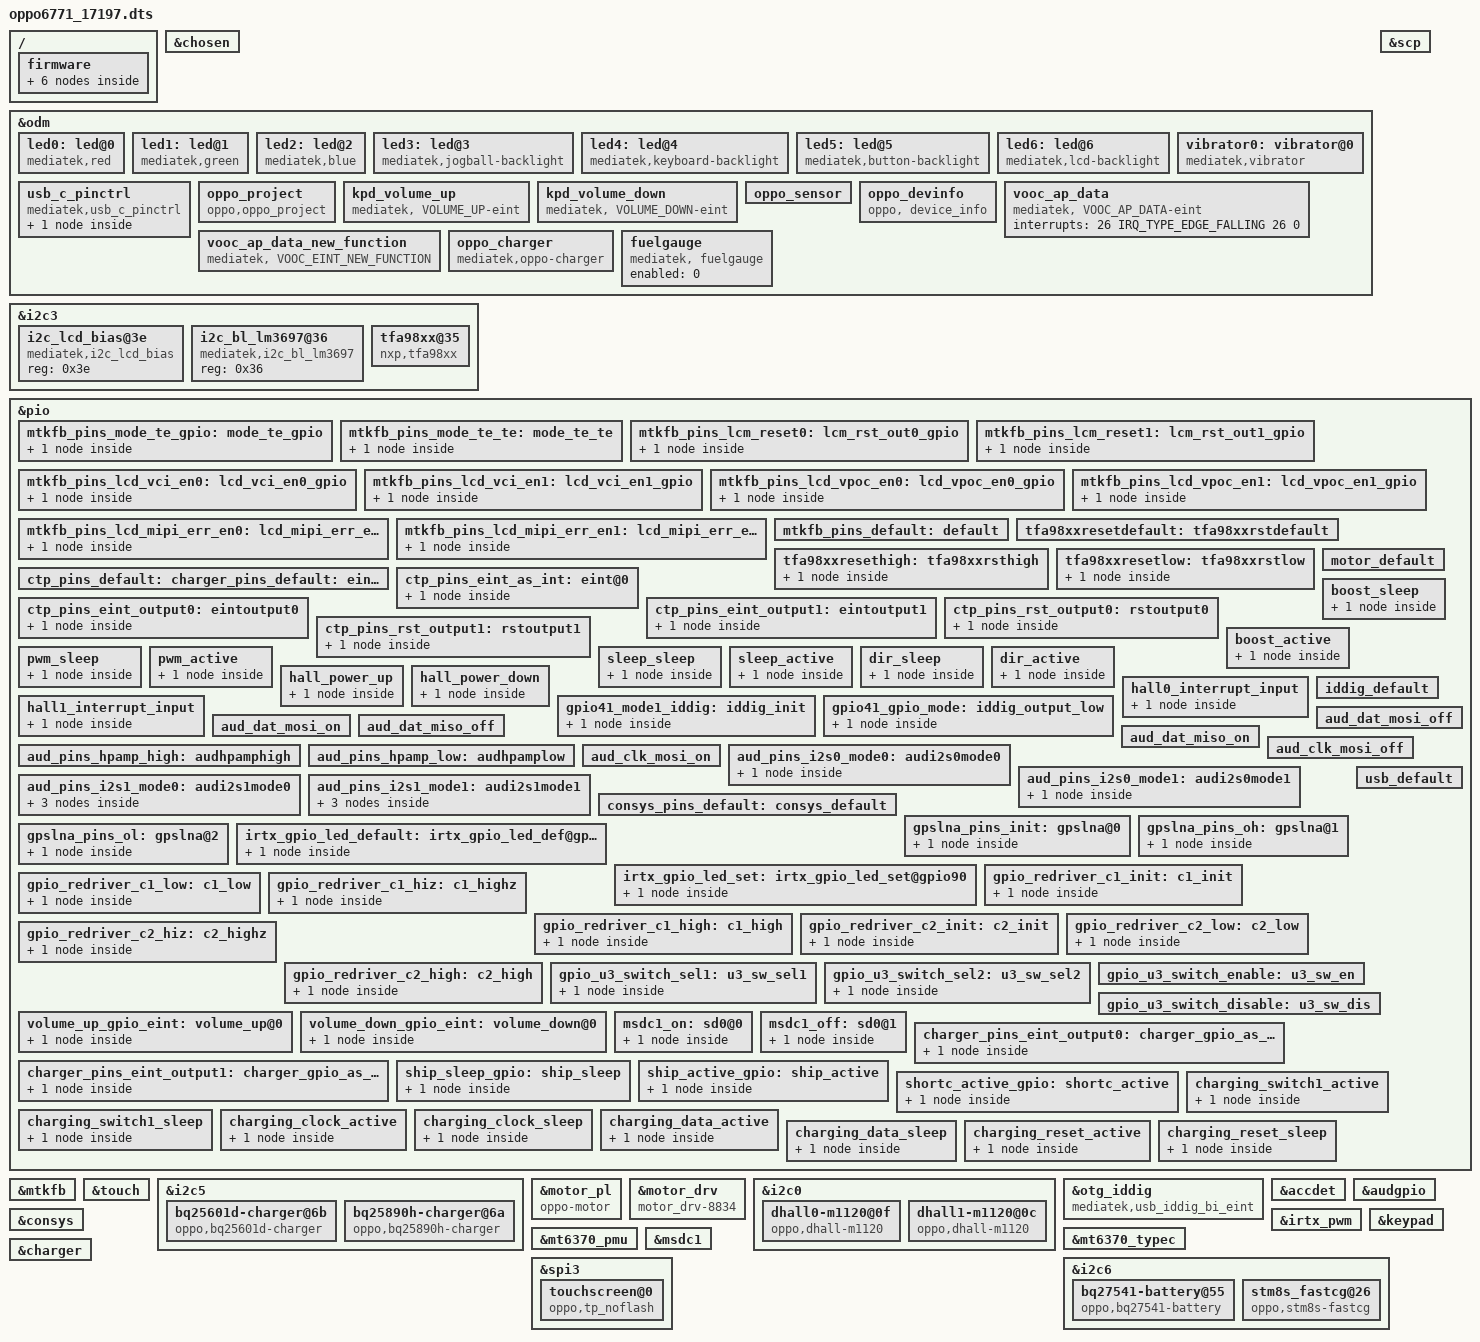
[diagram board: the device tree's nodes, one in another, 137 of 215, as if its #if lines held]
/*
 * Mediatek's mt6771 SoC device tree source
 *
 * Copyright (C) 2016 MediaTek Inc.
 *
 * This program is free software; you can redistribute it and/or modify
 * it under the terms of the GNU General Public License version 2 as
 * published by the Free Software Foundation.
 *
 * This program is distributed in the hope that it will be useful,
 * but WITHOUT ANY WARRANTY; without even the implied warranty of
 * MERCHANTABILITY or FITNESS FOR A PARTICULAR PURPOSE.
 * See http://www.gnu.org/licenses/gpl-2.0.html for more details.
 */
/dts-v1/;
/plugin/;
#include <dt-bindings/interrupt-controller/irq.h>
#include <dt-bindings/interrupt-controller/arm-gic.h>
#include <dt-bindings/pinctrl/mt6771-pinfunc.h>

/* chosen */
&chosen {
	/* fpga may has no lk, we need to specify display info here */
	/* fb buffer is reserved using this dts by memory node above */

	atag,videolfb-fb_base_l = <0x5e605000>;
	atag,videolfb-fb_base_h = <0x0>;
	atag,videolfb-islcmfound = <1>;
	atag,videolfb-islcm_inited = <0>;
	atag,videolfb-fps= <6000>;
	atag,videolfb-vramSize= <0x017bb000>;
	atag,videolfb-lcmname= "nt35595_fhd_dsi_cmd_truly_nt50358_drv";
};

/ {
	firmware {
		android {
			compatible = "android,firmware";
#ifndef CONFIG_MTK_LDVT
#ifdef CONFIG_MTK_AVB20_SUPPORT
			vbmeta {
				compatible = "android,vbmeta";
#ifndef CONFIG_MTK_AB_OTA_UPDATER
				parts = "vbmeta,boot,system,vendor,recovery";
#else
				parts = "vbmeta,boot,system,vendor";
#endif
			};
#endif
			fstab {
				compatible = "android,fstab";
#if !defined(CONFIG_SYSTEM_AS_ROOT) && !defined(CONFIG_MTK_AB_OTA_UPDATER)
				system {
					compatible = "android,system";
					dev = "/dev/block/platform/bootdevice/by-name/system";
					type = "ext4";
					mnt_flags = "ro";
#ifndef CONFIG_MTK_DM_VERITY_OFF
#ifdef CONFIG_MTK_AVB20_SUPPORT
					fsmgr_flags = "wait,avb";
#else
					fsmgr_flags = "wait,verify";
#endif
#else
					fsmgr_flags = "wait";
#endif
				};
#endif
#ifndef CONFIG_MTK_LATE_MOUNT
				vendor {
					compatible = "android,vendor";
					dev = "/dev/block/platform/bootdevice/by-name/vendor";
					type = "ext4";
					mnt_flags = "ro";
#ifndef CONFIG_MTK_AB_OTA_UPDATER
#ifndef CONFIG_MTK_DM_VERITY_OFF
#ifdef CONFIG_MTK_AVB20_SUPPORT
					fsmgr_flags = "wait,avb";
#else
					fsmgr_flags = "wait,verify";
#endif
#else
					fsmgr_flags = "wait";
#endif
#else
#ifndef CONFIG_MTK_DM_VERITY_OFF
#ifdef CONFIG_MTK_AVB20_SUPPORT
					fsmgr_flags = "wait,slotselect,avb";
#else
					fsmgr_flags = "wait,slotselect,verify";
#endif
#else
					fsmgr_flags = "wait,slotselect";
#endif
#endif
				};
#endif
#ifdef CONFIG_TARGET_COPY_OUT_ODM
				odm {
					compatible = "android,odm";
					dev = "/dev/block/platform/bootdevice/by-name/odm";
					type = "ext4";
					mnt_flags = "ro";
#ifndef CONFIG_MTK_AB_OTA_UPDATER
#ifndef CONFIG_MTK_DM_VERITY_OFF
#ifdef CONFIG_MTK_AVB20_SUPPORT
					fsmgr_flags = "wait,avb";
#else
					fsmgr_flags = "wait,verify";
#endif
#else
					fsmgr_flags = "wait";
#endif
#else
#ifndef CONFIG_MTK_DM_VERITY_OFF
#ifdef CONFIG_MTK_AVB20_SUPPORT
					fsmgr_flags = "wait,slotselect,avb";
#else
					fsmgr_flags = "wait,slotselect,verify";
#endif
#else
					fsmgr_flags = "wait,slotselect";
#endif
#endif
				};
#endif
			};
#endif
		};
	};
};

&odm {
//#ifdef VENDOR_EDIT
/* Qiao.Hu@BSP.BaseDrv.CHG.Basic, 2017/12/05, Add for charging dtsi */
#include "bat_setting/oppo_17197_mt6771_battery_prop_ext.dtsi"
//endif
	led0:led@0 {
		compatible = "mediatek,red";
		led_mode = <0>;
		data = <1>;
		pwm_config = <0 0 0 0 0>;
	};
	led1:led@1 {
		compatible = "mediatek,green";
		led_mode = <0>;
		data = <1>;
		pwm_config = <0 0 0 0 0>;
	};
	led2:led@2 {
		compatible = "mediatek,blue";
		led_mode = <0>;
		data = <1>;
		pwm_config = <0 0 0 0 0>;
	};
	led3:led@3 {
		compatible = "mediatek,jogball-backlight";
		led_mode = <0>;
		data = <1>;
		pwm_config = <0 0 0 0 0>;
	};
	led4:led@4 {
		compatible = "mediatek,keyboard-backlight";
		led_mode = <0>;
		data = <1>;
		pwm_config = <0 0 0 0 0>;
	};
	led5:led@5 {
		compatible = "mediatek,button-backlight";
		led_mode = <0>;
		data = <1>;
		pwm_config = <0 0 0 0 0>;
	};
	led6:led@6 {
		compatible = "mediatek,lcd-backlight";
		/* #ifndef VENDOR_EDIT */
		/* LiPing-m@PSW.MM.Display.LCD.Machine, 2017/11/03, Add for porting 17197 lcd driver */
		/* led_mode = <5>; */
		/* #else VENDOR_EDIT */
		led_mode = <4>;
		/* #endif VENDOR_EDIT */
		data = <1>;
		pwm_config = <0 1 0 0 0>;
	};
	vibrator0:vibrator@0 {
		compatible = "mediatek,vibrator";
		vib_timer = <30>;
		vib_limit = <0>;
		vib_vol= <11>;
	};
	usb_c_pinctrl:usb_c_pinctrl {
		compatible = "mediatek,usb_c_pinctrl";
	};
//#ifdef VENDOR_EDIT
/*Bin.Li@EXP.BSP.bootloader.bootflow, 2017/05/15, Add for oppo project */
	oppo_project:oppo_project {
		compatible = "oppo,oppo_project";
	};
//#endif /*VENDOR_EDIT*
/* Bin.Li@EXP.BSP.bootloader.bootflow, 2017/05/16, Add volume up and down */
       kpd_volume_up:kpd_volume_up {
               compatible = "mediatek, VOLUME_UP-eint";
               interrupt-parent = <&pio>;
               interrupts = <20 IRQ_TYPE_EDGE_FALLING 20 0>;
               debounce = <32000>;
               status = "okay";
       };

       kpd_volume_down:kpd_volume_down {
               compatible = "mediatek, VOLUME_DOWN-eint";
               interrupt-parent = <&pio>;
               interrupts = <94 IRQ_TYPE_EDGE_FALLING 94 0>;
               debounce = <32000>;
               status = "okay";
       };
//#endif
//#ifdef VENDOR_EDIT
/*Fei.Mo@PSW.BSP.Sensor, 2017/12/18, Add for sensor calibration paramaters */
       oppo_sensor:oppo_sensor {
       };
//#endif /*VENDOR_EDIT*
//ifdef VENDOR_EDIT
/* Bin.Li@EXP.BSP.bootloader.bootflow, 2017/07/07, Add device-info */
	oppo_devinfo:oppo_devinfo {
		compatible = "oppo, device_info";
	};
//endif
	//#ifdef VENDOR_EDIT
	// PengNan@BSP.chg.basic,2017/07/20,add for vooc support
	vooc_ap_data:vooc_ap_data {
		compatible = "mediatek, VOOC_AP_DATA-eint";
		interrupts = <26 IRQ_TYPE_EDGE_FALLING 26 0>;
	};
	vooc_ap_data_new_function:vooc_ap_data_new_function {
		compatible = "mediatek, VOOC_EINT_NEW_FUNCTION";
	};
	//#endif /*VENDOR_EDIT*/

	oppo_charger: oppo_charger {
		compatible = "mediatek,oppo-charger";
		pinctrl-names = "default", "charger_gpio_as_output_low", "charger_gpio_as_output_high", "ship_sleep", "ship_active", "shortc_active";
		pinctrl-0 = <&charger_pins_default>;
		pinctrl-1 = <&charger_pins_eint_output0>;
		pinctrl-2 = <&charger_pins_eint_output1>;
		pinctrl-3 = <&ship_sleep_gpio>;
		pinctrl-4 = <&ship_active_gpio>;
		pinctrl-5 = <&shortc_active_gpio>;

		//for oppo chg framework:
		qcom,input_current_charger_ma = <2000>;
		qcom,input_current_cdp_ma = <1500>;
		qcom,input_current_usb_ma = <500>;
		qcom,input_current_led_ma = <1200>;
		qcom,input_current_led_ma_forcmcc = <500>;
		qcom,input_current_camera_ma = <1200>;
		qcom,input_current_calling_ma = <1500>;

		qcom,iterm_disabled = <0>;
		qcom,iterm_ma = <200>;
		qcom,recharge-mv = <115>;

		qcom,batt_capacity_mah = <4000>; /*typical capacity*/
		//qcom,batt_capacity_mah = <3900>; /*rated capacity*/

		qcom,removed_bat_decidegc = <190>;  /* < -19C */

		qcom,cold_bat_decidegc = <20>;  /* -3C ~ 0C */
		qcom,temp_cold_vfloat_mv = <3980>;
		qcom,temp_cold_fastchg_current_ma = <360>;

		qcom,little_cold_bat_decidegc = <0>;	/* 0C ~ 5C */
		qcom,temp_little_cold_vfloat_mv = <4385>;
		qcom,temp_little_cold_fastchg_current_ma_high = <1850>;
		qcom,temp_little_cold_fastchg_current_ma_low = <1100>;
		qcom,temp_little_cold_fastchg_current_ma = <1100>;

		qcom,cool_bat_decidegc = <50>;	/* 5C ~ 12C */
		qcom,temp_cool_vfloat_mv = <4385>;
		qcom,temp_cool_fastchg_current_ma_high = <2100>;
		qcom,temp_cool_fastchg_current_ma_low = <1850>;

		qcom,little_cool_bat_decidegc = <120>;	/* 12C ~ 16C */
		qcom,temp_little_cool_vfloat_mv = <4385>;
		qcom,temp_little_cool_fastchg_current_ma = <2100>;

		qcom,normal_bat_decidegc = <160>;	/* 16C ~ 45C */
		qcom,temp_normal_fastchg_current_ma = <2100>;
		qcom,temp_normal_vfloat_mv = <4385>;

		qcom,warm_bat_decidegc = <480>;		/* 45C ~ 53C */ /*8pin Bat Vooc project need add 3 degree C*/
		qcom,temp_warm_vfloat_mv = <4130>;
		qcom,temp_warm_fastchg_current_ma = <1100>;

		qcom,hot_bat_decidegc = <530>;  /* > 53C */

		qcom,non_standard_vfloat_mv = <3980>;
		qcom,non_standard_fastchg_current_ma = <512>;

		qcom,short_c_bat_cv_mv = <4330>;
		qcom,short_c_bat_vfloat_mv = <3800>;
		qcom,short_c_bat_fastchg_current_ma = <512>;
		qcom,short_c_bat_vfloat_sw_limit = <3750>;

		qcom,cold_vfloat_sw_limit = <3930>;
		qcom,little_cold_vfloat_sw_limit = <4335>;
		qcom,cool_vfloat_sw_limit = <4335>;
		qcom,little_cool_vfloat_sw_limit = <4335>;
		qcom,normal_vfloat_sw_limit = <4335>;
		qcom,warm_vfloat_sw_limit = <4080>;
		qcom,non_standard_vfloat_sw_limit = <3930>;

		qcom,max_chg_time_sec = <36000>;
		qcom,charger_hv_thr = <5800>;
		qcom,charger_lv_thr = <3400>;
		qcom,vbatt_full_thr = <4400>;
		qcom,vbatt_hv_thr = <4500>;
	
		qcom,vfloat_step_mv = <16>;
		qcom,non_standard_vfloat_over_sw_limit = <3980>;
		qcom,cold_vfloat_over_sw_limit = <3980>;
		qcom,little_cold_vfloat_over_sw_limit = <4390>;
		qcom,cool_vfloat_over_sw_limit = <4390>;
		qcom,little_cool_vfloat_over_sw_limit = <4390>;
		qcom,normal_vfloat_over_sw_limit = <4390>;
		qcom,warm_vfloat_over_sw_limit = <4130>;

		qcom,vbatt_power_off = <3300>;
		qcom,vbatt_soc_1 = <3410>;
		qcom,vooc_project = <1>;
		qcom,vbatt_num = <1>;

		qcom,normal_vterm_hw_inc = <150>;
		qcom,non_normal_vterm_hw_inc = <10>;

		qcom,ff1_normal_fastchg_ma = <1088>;
		qcom,ffc2_normal_fastchg_ma = <780>;/*16C~35c*/
		qcom,ffc2_temp_warm_decidegc = <350>;
		qcom,ffc2_warm_fastchg_ma = <840>;/*35C~40c*/
		qcom,ffc2_temp_high_decidegc = <400>;
		qcom,ffc2_temp_low_decidegc = <120>;
		qcom,ff1_exit_step_ma = <488>;
		qcom,ff1_warm_exit_step_ma = <418>;
		qcom,ffc2_exit_step_ma = <180>;
		qcom,ffc2_warm_exit_step_ma = <170>;

		qcom,ffc_normal_vfloat_sw_limit = <4430>;
		qcom,ffc_temp_normal_vfloat_mv = <4500>;
		qcom,ffc_normal_vfloat_over_sw_limit = <4500>;

		qcom,default_iterm_ma = <200>;
		qcom,default_temp_normal_fastchg_current_ma = <2100>;
		qcom,default_normal_vfloat_sw_limit = <4335>;
		qcom,default_temp_normal_vfloat_mv = <4385>;
		qcom,default_normal_vfloat_over_sw_limit = <4390>;

		//for 2nd chip:
		qcom,iterm_ma_2nd = <300>;
		qcom,recharge-mv_2nd = <121>;

		qcom,temp_little_cold_vfloat_mv_2nd = <4391>;	/* 0C ~ 5C */
		qcom,temp_cool_vfloat_mv_2nd = <4391>;	/* 5C ~ 12C */
		qcom,temp_little_cool_vfloat_mv_2nd = <4391>;	/* 12C ~ 16C */
		qcom,temp_normal_vfloat_mv_2nd = <4391>;	/* 16C ~ 45C */

		qcom,little_cold_vfloat_over_sw_limit_2nd = <4395>;
		qcom,cool_vfloat_over_sw_limit_2nd = <4395>;
		qcom,little_cool_vfloat_over_sw_limit_2nd = <4395>;
		qcom,normal_vfloat_over_sw_limit_2nd = <4395>;

		qcom,default_iterm_ma_2nd = <300>;
		qcom,default_temp_normal_vfloat_mv_2nd = <4391>;
		qcom,default_normal_vfloat_over_sw_limit_2nd = <4395>;

		//for control:
		//qcom,suspend_after_full;
		qcom,check_batt_full_by_sw;
		qcom,external_gauge;
		qcom,chg_ctrl_by_calling;
		qcom,chg_ctrl_by_lcd;
		qcom,chg_ctrl_by_camera;
		qcom,sw_vfloat_over_protect_enable;
		qcom,ffc_support;

		//GPIO config:
		qcom,chargerid_switch-gpio = <&pio 97 0x00>;
		qcom,ship-gpio = <&pio 155 0x00>;
		qcom,shortc-gpio = <&pio 77 0x00>;
	};
	
//#ifdef VENDOR_EDIT
//PengNan@BSP.CHG.Basic, 2017/09/07, add for compatabling two fuelgauge.
	fuelgauge: fuelgauge {
		compatible = "mediatek, fuelgauge";
	};
//#endif
};

&scp {
	core_1 = "enable";
	scp_sramSize = <0x00080000>;     /* scp_A_sram_size */
};


/* #ifdef VENDOR_EDIT */
/* LiPing-m@PSW.MM.Display.LCD.Machine, 2017/11/03, Add for porting 17197 lcd driver */
&i2c3 {
    #address-cells = <1>;
    #size-cells = <0>;

       i2c_lcd_bias@3e {
               compatible = "mediatek,i2c_lcd_bias";
               reg = <0x3e>;
               status = "okay";
       };
       i2c_bl_lm3697@36 {
               compatible = "mediatek,i2c_bl_lm3697";
               reg = <0x36>;
               status = "okay";
       };
};

&pio {
	mtkfb_pins_mode_te_gpio: mode_te_gpio {
		pins_cmd_dat {
			pinmux = <PINMUX_GPIO44__FUNC_GPIO44>;
	};
		};

	mtkfb_pins_mode_te_te: mode_te_te {
		pins_cmd_dat {
			pinmux = <PINMUX_GPIO44__FUNC_DSI_TE>;
		};
	};

	mtkfb_pins_lcm_reset0: lcm_rst_out0_gpio {
		pins_cmd_dat {
			pinmux = <PINMUX_GPIO45__FUNC_GPIO45>;
			slew-rate = <1>;
			output-low;
		};
	};

	mtkfb_pins_lcm_reset1: lcm_rst_out1_gpio {
		pins_cmd_dat {
			pinmux = <PINMUX_GPIO45__FUNC_GPIO45>;
			slew-rate = <1>;
			output-high;
		};
	};

	mtkfb_pins_lcd_vci_en0: lcd_vci_en0_gpio {
		pins_cmd_dat {
			pinmux = <PINMUX_GPIO179__FUNC_GPIO179>;
			slew-rate = <1>;
			output-low;
		};
	};

	mtkfb_pins_lcd_vci_en1: lcd_vci_en1_gpio {
		pins_cmd_dat {
			pinmux = <PINMUX_GPIO179__FUNC_GPIO179>;
			slew-rate = <1>;
			output-high;
		};
	};

	mtkfb_pins_lcd_vpoc_en0: lcd_vpoc_en0_gpio {
		pins_cmd_dat {
			pinmux = <PINMUX_GPIO25__FUNC_GPIO25>;
			slew-rate = <1>;
			output-low;
		};
	};

	mtkfb_pins_lcd_vpoc_en1: lcd_vpoc_en1_gpio {
		pins_cmd_dat {
			pinmux = <PINMUX_GPIO25__FUNC_GPIO25>;
			slew-rate = <1>;
			output-high;
		};
	};

	mtkfb_pins_lcd_mipi_err_en0: lcd_mipi_err_en0_gpio {
		pins_cmd_dat {
			pinmux = <PINMUX_GPIO178__FUNC_GPIO178>;
			slew-rate = <1>;
			output-low;
		};
	};

	mtkfb_pins_lcd_mipi_err_en1: lcd_mipi_err_en1_gpio {
		pins_cmd_dat {
			pinmux = <PINMUX_GPIO178__FUNC_GPIO178>;
			slew-rate = <1>;
			output-high;
		};
	};

	mtkfb_pins_default: default {
};
};

&mtkfb {
	pinctrl-names = "default", "mode_te_gpio", "mode_te_te", "lcm_rst_out0_gpio",
	"lcm_rst_out1_gpio", "lcd_vci_en0_gpio", "lcd_vci_en1_gpio","lcd_vpoc_en0_gpio",
	"lcd_vpoc_en1_gpio","lcd_mipi_err_en0_gpio", "lcd_mipi_err_en1_gpio";
	pinctrl-0 = <&mtkfb_pins_default>;
	pinctrl-1 = <&mtkfb_pins_mode_te_gpio>;
	pinctrl-2 = <&mtkfb_pins_mode_te_te>;
	pinctrl-3 = <&mtkfb_pins_lcm_reset0>;
	pinctrl-4 = <&mtkfb_pins_lcm_reset1>;
	pinctrl-5 = <&mtkfb_pins_lcd_vci_en0>;
	pinctrl-6 = <&mtkfb_pins_lcd_vci_en1>;
	pinctrl-7 = <&mtkfb_pins_lcd_vpoc_en0>;
	pinctrl-8 = <&mtkfb_pins_lcd_vpoc_en1>;
	pinctrl-9 = <&mtkfb_pins_lcd_mipi_err_en0>;
	pinctrl-10 = <&mtkfb_pins_lcd_mipi_err_en1>;
	status = "okay";
	oppo_display_hbm_support;
	oppo_display_ffl_support;
	oppo_display_panelid_support;
	oppo_display_panelnum_support;
	oppo_display_sau_support;
	oppo_display_fppress_support;
};
/* #endif VENDOR_EDIT */

//#ifdef VENDOR_EDIT
/* hongxiang.jin@PSW.MM.AudioDriver.Machine, 2019/08/26,
 * Modify for tfa I2C & gpio config */
&i2c3 {
    #address-cells = <1>;
    #size-cells = <0>;

    tfa98xx@35 {
        compatible = "nxp,tfa98xx";
        reg = <0x35>;
        status = "okay";
        pinctrl-names = "tfa98xx_reset_default", "tfa98xx_reset_high", "tfa98xx_reset_low";
        pinctrl-0 = <&tfa98xxresetdefault>;
        pinctrl-1 = <&tfa98xxresethigh>;
        pinctrl-2 = <&tfa98xxresetlow>;
    };
};

&pio {
	tfa98xxresetdefault: tfa98xxrstdefault {
	};

	tfa98xxresethigh: tfa98xxrsthigh {
		pins_cmd_dat {
			pinmux = <PINMUX_GPIO156__FUNC_GPIO156>;
			slew-rate = <1>;
			output-high;
		};
	};

	tfa98xxresetlow: tfa98xxrstlow {
		pins_cmd_dat {
			pinmux = <PINMUX_GPIO156__FUNC_GPIO156>;
			slew-rate = <1>;
			output-low;
		};
	};
};
//#endif /* VENDOR_EDIT */

/* TOUCH start */
&touch {
	tpd-resolution = <1080 1920>;
	use-tpd-button = <0>;
	tpd-key-num = <3>;
	tpd-key-local= <139 172 158 0>;
	tpd-key-dim-local = <90 883 100 40 230 883 100 40 370 883 100 40 0 0 0 0>;
	tpd-max-touch-num = <5>;
	tpd-filter-enable = <1>;
	tpd-filter-pixel-density = <146>;
	tpd-filter-custom-prameters = <0 0 0 0 0 0 0 0 0 0 0 0>;
	tpd-filter-custom-speed = <0 0 0>;
	pinctrl-names = "default", "state_eint_as_int", "state_eint_output0", "state_eint_output1",
		"state_rst_output0", "state_rst_output1";
	pinctrl-0 = <&ctp_pins_default>;
	pinctrl-1 = <&ctp_pins_eint_as_int>;
	pinctrl-2 = <&ctp_pins_eint_output0>;
	pinctrl-3 = <&ctp_pins_eint_output1>;
	pinctrl-4 = <&ctp_pins_rst_output0>;
	pinctrl-5 = <&ctp_pins_rst_output1>;
	status = "okay";
};
&pio {
	ctp_pins_default: eint0default {
	};
	ctp_pins_eint_as_int: eint@0 {
		pins_cmd_dat {
			pinmux = <PINMUX_GPIO1__FUNC_GPIO1>;
			slew-rate = <0>;
			bias-disable;
		};
	};
	ctp_pins_eint_output0: eintoutput0 {
		pins_cmd_dat {
			pinmux = <PINMUX_GPIO1__FUNC_GPIO1>;
			slew-rate = <1>;
			output-low;
		};
	};
	ctp_pins_eint_output1: eintoutput1 {
		pins_cmd_dat {
			pinmux = <PINMUX_GPIO1__FUNC_GPIO1>;
			slew-rate = <1>;
			output-high;
		};
	};
	ctp_pins_rst_output0: rstoutput0 {
		pins_cmd_dat {
			pinmux = <PINMUX_GPIO2__FUNC_GPIO2>;
			slew-rate = <1>;
			output-low;
		};
	};
	ctp_pins_rst_output1: rstoutput1 {
		pins_cmd_dat {
			pinmux = <PINMUX_GPIO2__FUNC_GPIO2>;
			slew-rate = <1>;
			output-high;
		};
	};
};
/* TOUCH end */
//#ifdef VENDOR_EDIT
//PengNan@BSP.CHG.Basic, 2017/09/07, add for compatabling two fuelgauge.
&fuelgauge{
	enabled = <0>;
};
//#endif

//#ifdef VENDOR_EDIT
/* Qiao.Hu@BSP.BaseDrv.CHG.Basic, 2017/11/19, Add for charging */
&i2c5 {

	bq25601d-charger@6b {
		status = "okay";
		compatible = "oppo,bq25601d-charger";
		reg = <0x6b>;
		chip-name = "BQ25601D";
		interrupt-parent = <&pio>;
		interrupts = <91 IRQ_TYPE_EDGE_FALLING 91 0>;
		chg-irq-gpio = <&pio 91 0x2002>;
	};

	bq25890h-charger@6a {
		status = "okay";
		compatible = "oppo,bq25890h-charger";
		reg = <0x6a>;
		chip-name = "BQ25890H";
		interrupt-parent = <&pio>;
		interrupts = <91 IRQ_TYPE_EDGE_FALLING 91 0>;
		chg-irq-gpio = <&pio 91 0x2002>;
	};
};
//#ifdef VENDOR_EDIT
//Fei.Mo@PSW.BSP.Sensor 2018-03-24, Add for motor direction switch

&pio {
    motor_default:motor_default {
    };

    boost_sleep: boost_sleep {
        pins_cmd_dat {
            pinmux = <PINMUX_GPIO15__FUNC_GPIO15>;
            slew-rate = <1>;
            bias-pull-down; //pull down
            output-low; //digital output, no invert
            drive-strength = <3>;//0.15
        };
    };

    boost_active: boost_active {
        pins_cmd_dat {
            pinmux = <PINMUX_GPIO15__FUNC_GPIO15>;
            slew-rate = <1>;
            bias-disable; //pull down
            output-high; //digital output, no invert
            drive-strength = <3>;//0.15
        };
    };

    pwm_sleep: pwm_sleep {
        pins_cmd_dat {
            pinmux = <PINMUX_GPIO90__FUNC_GPIO90>;
            slew-rate = <1>;
            bias-pull-up; //digital output, no invert
	    output-high;
            drive-strength = <0>; //LOW strength
        };
    };

    pwm_active: pwm_active {
        pins_cmd_dat {
            pinmux = <PINMUX_GPIO90__FUNC_PWM_A>;
            slew-rate = <1>;
            bias-disable; //No Pull
	    output-low;
            drive-strength = <0>; //LOW strength
        };
    };

    sleep_sleep: sleep_sleep {
        pins_cmd_dat {
            pinmux = <PINMUX_GPIO14__FUNC_GPIO14>;
	    slew-rate = <1>;
            bias-pull-up;
	    output-high;
            drive-strength = <0>; /* LOW strength */
        };
    };

    sleep_active: sleep_active {
        pins_cmd_dat {
            pinmux = <PINMUX_GPIO14__FUNC_GPIO14>;
            slew-rate = <1>;
            bias-disable; /* No Pull */
            output-low; /* digital output, no invert */
            drive-strength = <0>; /* LOW strength */
        };
    };

    dir_sleep: dir_sleep {
        pins_cmd_dat {
            pinmux = <PINMUX_GPIO16__FUNC_GPIO16>;
	    slew-rate = <1>;
            bias-pull-up;
	    output-high;
            drive-strength = <0>; /* LOW strength */
        };
    };

    dir_active: dir_active {
        pins_cmd_dat {
            pinmux = <PINMUX_GPIO16__FUNC_GPIO16>;
	    slew-rate = <1>;
            bias-disable; /* No Pull */
            output-low; /* digital output, no invert */
            drive-strength = <0>; /* LOW strength */
        };
    };
};

&motor_pl {
	status = "okay";
	compatible = "oppo-motor";
	hall-irq-pos = <170>;
	motor-retard-pos = <430>;
	delay-cycle = <14 14 14>; //ms
	slow-delay-cycle = <28 28 28>; //ms
	full-speed-param = <63 15500>;
	up-speed-param = <5 15500>;
	down-speed-param = <2 156250>;
	nodetect-speed-param = <15 15500>;
	slow-full-speed-param = <63 31250>;
	slow-up-speed-param = <5 104166>;
	slow-down-speed-param = <2 156250>;
	slow-nodetect-speed-param = <15 104166>;
	stop-neg-point = <3 3>;
	stop-pos-point = <3 3>;
	hall-data-sign = <0>; //1 represent positive ,0 represent negative
	/*support mag noise decrease*/
	mag_noise_support;
	mag_noise_pattern = <80 400 0 662 200 100 100>;
};

&motor_drv {
	status = "okay";
	compatible = "motor_drv-8834";
	pinctrl-names = "default","motor_sleep","motor_active";
	pinctrl-0 = <&motor_default>;
	pinctrl-1 = <&sleep_sleep &pwm_sleep &dir_sleep &boost_sleep>;
	pinctrl-2 = <&sleep_active &pwm_active &dir_active &boost_active>;
	boost-gpio = <&pio 15 0x00>;
	sleep-gpio = <&pio 14 0>;
	dir-gpio = <&pio 16 0>;
	step-gpio = <&pio 90 0>;
	ratio-a = <24>;
	ratio-b = <1840>;//18.40
	ratio-c = <20>;
	ratio-d = <32>;
};

&i2c0 {
	status = "okay";
    dhall0-m1120@0f {
        status = "okay";
        compatible = "oppo,dhall-m1120";
        reg = <0x0f>;
        pinctrl-names = "hall_power_down","hall_power_up","hall0_interrupt_input";
        pinctrl-0 = <&hall_power_down>;
        pinctrl-1 = <&hall_power_up>;
        pinctrl-2 = <&hall0_interrupt_input>;
        interrupt-parent = <&pio>;
        interrupts = <5 IRQ_TYPE_LEVEL_LOW 5 0>;
        dhall,irq-gpio = <&pio 5 0x2008>;
        dhall,id = <0>;
        hall-power-gpio = <&pio 110 0>;
	};

    dhall1-m1120@0c {
    	status = "okay";
        compatible = "oppo,dhall-m1120";
        reg = <0x0c>;
        pinctrl-names = "hall_power_down","hall_power_up","hall1_interrupt_input";
        pinctrl-0 = <&hall_power_down>;
        pinctrl-1 = <&hall_power_up>;
        pinctrl-2 = <&hall1_interrupt_input>;
        interrupt-parent = <&pio>;
        interrupts = <6 IRQ_TYPE_LEVEL_LOW 6 0>;
        dhall,irq-gpio = <&pio 6 0x2008>;
        dhall,id = <1>;
        hall-power-gpio = <&pio 110 0>;
	};
};

&pio {
    hall_power_up: hall_power_up {
        pins_cmd_dat {
            pinmux = <PINMUX_GPIO110__FUNC_GPIO110>;
            slew-rate = <1>;
            drive-strength = <2>;
            output-high;
            bias-pull-down;
		};
	};
    hall_power_down: hall_power_down {
        pins_cmd_dat {
            pinmux = <PINMUX_GPIO110__FUNC_GPIO110>;
            slew-rate = <1>;
            drive-strength = <2>;
            output-low;
            bias-pull-down;
        };
    };
    hall0_interrupt_input: hall0_interrupt_input {
        pins_cmd_dat {
            pinmux = <PINMUX_GPIO6__FUNC_GPIO6>;
            slew-rate = <0>;
            drive-strength = <2>;
            bias-disable; //No Pull
        };
    };
    hall1_interrupt_input: hall1_interrupt_input {
        pins_cmd_dat {
            pinmux = <PINMUX_GPIO5__FUNC_GPIO5>;
            slew-rate = <0>;
            drive-strength = <2>;
            bias-disable; //No Pull
        };
    };
};
//#endif
//#endif /* VENDOR_EDIT */
/* Qiao.Hu@@Prd6.BaseDrv.USB.Basic, 2017/07/25, Add for otg */
&otg_iddig {
	/* Qiao.Hu@EXP.BSP.CHG.basic, 2017/05/09, Add for otg support */
	compatible = "mediatek,usb_iddig_bi_eint";
	pinctrl-names = "iddig_default", "iddig_init", "iddig_output_low" ;
	pinctrl-0 = <&iddig_default>;
	pinctrl-1 = <&gpio41_mode1_iddig>;
	pinctrl-2 = <&gpio41_gpio_mode>;
	status = "okay";
    	/* Qiao.Hu@EXP.BSP.CHG.basic, 2017/05/25, Add for OTG GPIO */
	qcom,otg_switch_gpio = <41>;

};
&pio {
	iddig_default: iddig_default {
	};
	//#ifdef VENDOR_EDIT
	/* Qiao.Hu@EXP.BSP.CHG.basic, 2017/11/28, Add for otg support */
	gpio41_mode1_iddig: iddig_init {
		pins_cmd_dat {
			pinmux = <PINMUX_GPIO41__FUNC_IDDIG>;
			slew-rate = <0>;
			bias-pull-up = <101>;
		};
	};
	gpio41_gpio_mode: iddig_output_low {
		pins_cmd_dat {
			pinmux = <PINMUX_GPIO41__FUNC_GPIO41>;
			slew-rate = <1>;
			output-low;
		};
	};

	//#endif /* VENDOR_EDIT */
};
/* accdet start */
&accdet {
	/* accdet micbias voltage: 0x07,2.7v;0x05,2.5v;0x02,1.9v */
	//#ifdef VENDOR_EDIT
	//Yongzhi.Zhang@PSW.MM.AudioDriver.Codec, 2018/03/10,
	//modify for changing micbias vol to 2.7V for headset mic
	accdet-mic-vol = <7>;
	//#else /* VENDOR_EDIT */
	//accdet-mic-vol = <6>;
	//#endif /* VENDOR_EDIT */
	headset-mode-setting = <0x500 0x500 1 0x1f0 0x800 0x800 0x20 0x44>;
	accdet-plugout-debounce = <1>;
	/*1:ACC mode, 2:low cost without in bias, 6:low cost with in bias*/
	accdet-mic-mode = <1>;
	/* eint_level_trigger: 8,LEVEL_LOW(default);4,LEVEL_HIGH;others,LEVEL_LOW */
	headset-eint-level-pol = <8>;
	/*0--MD_MAX--UP_MAX--DW_MAX*/
	headset-three-key-threshold = <0 80 220 400>;
	headset-three-key-threshold-CDD = <0 121 192 600>;
	/*0--MD_MAX--VOICE_MAX--UP_MAX--DW_MAX*/
	headset-four-key-threshold = <0 58 121 192 400>;
	status = "okay";
};
/* accdet end */
//#ifdef VENDOR_EDIT
/* Yongzhi.Zhang@PSW.MM.AudioDriver.Machine, 2017/11/22,
 * Modify for audio gpio config */
&audgpio {
	pinctrl-names = "aud_dat_mosi_off",
			"aud_dat_mosi_on",
			"aud_dat_miso_off",
			"aud_dat_miso_on",
			"hpamp-pullhigh",
			"hpamp-pulllow",
			"aud_clk_mosi_off",
			"aud_clk_mosi_on",
			"audi2s0-mode0",
			"audi2s0-mode1",
			"audi2s1-mode0",
			"audi2s1-mode1";
	pinctrl-0 = <&aud_dat_mosi_off>;
	pinctrl-1 = <&aud_dat_mosi_on>;
	pinctrl-2 = <&aud_dat_miso_off>;
	pinctrl-3 = <&aud_dat_miso_on>;
	pinctrl-4 = <&aud_pins_hpamp_high>;
	pinctrl-5 = <&aud_pins_hpamp_low>;
	pinctrl-6 = <&aud_clk_mosi_off>;
	pinctrl-7 = <&aud_clk_mosi_on>;
	pinctrl-8 = <&aud_pins_i2s0_mode0>;
	pinctrl-9 = <&aud_pins_i2s0_mode1>;
	pinctrl-10 = <&aud_pins_i2s1_mode0>;
	pinctrl-11 = <&aud_pins_i2s1_mode1>;
	status = "okay";
};

&pio {
	aud_dat_mosi_off: aud_dat_mosi_off {
	};

	aud_dat_mosi_on: aud_dat_mosi_on {
	};

	aud_dat_miso_off: aud_dat_miso_off {
	};

	aud_dat_miso_on: aud_dat_miso_on {
	};

	aud_pins_hpamp_high: audhpamphigh {
	};

	aud_pins_hpamp_low: audhpamplow {
	};

	aud_clk_mosi_off: aud_clk_mosi_off {
	};

	aud_clk_mosi_on: aud_clk_mosi_on {
	};

	aud_pins_i2s0_mode0: audi2s0mode0 {
		pins_cmd_dat {
			pinmux = <PINMUX_GPIO174__FUNC_GPIO174>;
		};
	};
	aud_pins_i2s0_mode1: audi2s0mode1 {
		pins_cmd_dat {
			pinmux = <PINMUX_GPIO174__FUNC_I2S0_DI>;
		};
	};
	aud_pins_i2s1_mode0: audi2s1mode0 {
		pins_cmd0_dat {
			pinmux = <PINMUX_GPIO170__FUNC_GPIO170>;
		};
		pins_cmd1_dat {
			pinmux = <PINMUX_GPIO171__FUNC_GPIO171>;
		};
		pins_cmd2_dat {
			pinmux = <PINMUX_GPIO172__FUNC_GPIO172>;
		};
	};
	/* Yongzhi.Zhang@PSW.MM.AudioDriver.Machine, 2018/01/06,
	 * change I2S1 to I2S3 by MTK's suggestion */
	aud_pins_i2s1_mode1: audi2s1mode1 {
		pins_cmd0_dat {
			pinmux = <PINMUX_GPIO170__FUNC_I2S3_BCK>;
		};
		pins_cmd1_dat {
			pinmux = <PINMUX_GPIO171__FUNC_I2S3_LRCK>;
		};
		pins_cmd2_dat {
			pinmux = <PINMUX_GPIO172__FUNC_I2S3_DO>;
		};
	};
};
//#else /*VENDOR_EDIT*/
/* AUDIO GPIO standardization */
/*
&audgpio {
	pinctrl-names = "aud_clk_mosi_off",
			"aud_clk_mosi_on",
			"aud_dat_mosi_off",
			"aud_dat_mosi_on",
			"aud_dat_miso_off",
			"aud_dat_miso_on",
			"aud_smartpa_off",
			"aud_smartpa_on",
			"vow_dat_miso_off",
			"vow_dat_miso_on",
			"vow_clk_miso_off",
			"vow_clk_miso_on";
	pinctrl-0 = <&aud_clk_mosi_off>;
	pinctrl-1 = <&aud_clk_mosi_on>;
	pinctrl-2 = <&aud_dat_mosi_off>;
	pinctrl-3 = <&aud_dat_mosi_on>;
	pinctrl-4 = <&aud_dat_miso_off>;
	pinctrl-5 = <&aud_dat_miso_on>;
	pinctrl-6 = <&aud_pins_smartpa_off>;
	pinctrl-7 = <&aud_pins_smartpa_on>;
	pinctrl-8 = <&vow_dat_miso_off>;
	pinctrl-9 = <&vow_dat_miso_on>;
	pinctrl-10 = <&vow_clk_miso_off>;
	pinctrl-11 = <&vow_clk_miso_on>;
	status = "okay";
};

&pio {
	aud_clk_mosi_off: aud_clk_mosi_off {
		pins_cmd0_dat {
			pinmux = <PINMUX_GPIO136__FUNC_GPIO136>;
			input-enable;
			slew-rate = <0>;
			bias-disable;
		};
		pins_cmd1_dat {
			pinmux = <PINMUX_GPIO137__FUNC_GPIO137>;
			input-enable;
			slew-rate = <0>;
			bias-disable;
		};
	};

	aud_clk_mosi_on: aud_clk_mosi_on {
		pins_cmd0_dat {
			pinmux = <PINMUX_GPIO136__FUNC_AUD_CLK_MOSI>;
			input-schmitt-enable;
		};
		pins_cmd1_dat {
			pinmux = <PINMUX_GPIO137__FUNC_AUD_SYNC_MOSI>;
			input-schmitt-enable;
		};
	};

	aud_dat_mosi_off: aud_dat_mosi_off {
		pins_cmd0_dat {
			pinmux = <PINMUX_GPIO138__FUNC_GPIO138>;
			input-enable;
			slew-rate = <0>;
			bias-disable;
		};
		pins_cmd1_dat {
			pinmux = <PINMUX_GPIO139__FUNC_GPIO139>;
			input-enable;
			slew-rate = <0>;
			bias-pull-down;
		};
	};

	aud_dat_mosi_on: aud_dat_mosi_on {
		pins_cmd0_dat {
			pinmux = <PINMUX_GPIO138__FUNC_AUD_DAT_MOSI0>;
			input-schmitt-enable;
		};
		pins_cmd1_dat {
			pinmux = <PINMUX_GPIO139__FUNC_AUD_DAT_MOSI1>;
			input-schmitt-enable;
		};
	};

	aud_dat_miso_off: aud_dat_miso_off {
		pins_cmd0_dat {
			pinmux = <PINMUX_GPIO140__FUNC_GPIO140>;
			input-enable;
			slew-rate = <0>;
			bias-disable;
		};
		pins_cmd1_dat {
			pinmux = <PINMUX_GPIO141__FUNC_GPIO141>;
			input-enable;
			slew-rate = <0>;
			bias-disable;
		};
		pins_cmd2_dat {
			pinmux = <PINMUX_GPIO142__FUNC_GPIO142>;
			input-enable;
			slew-rate = <0>;
			bias-disable;
		};
		pins_cmd3_dat {
			pinmux = <PINMUX_GPIO143__FUNC_GPIO143>;
			input-enable;
			slew-rate = <0>;
			bias-disable;
		};
	};

	aud_dat_miso_on: aud_dat_miso_on {
		pins_cmd0_dat {
			pinmux = <PINMUX_GPIO140__FUNC_AUD_CLK_MISO>;
			input-schmitt-enable;
		};
		pins_cmd1_dat {
			pinmux = <PINMUX_GPIO141__FUNC_AUD_SYNC_MISO>;
			input-schmitt-enable;
		};
		pins_cmd2_dat {
			pinmux = <PINMUX_GPIO142__FUNC_AUD_DAT_MISO0>;
			input-schmitt-enable;
		};
		pins_cmd3_dat {
			pinmux = <PINMUX_GPIO143__FUNC_AUD_DAT_MISO1>;
			input-schmitt-enable;
		};
	};

	aud_pins_smartpa_off: aud_pins_smartpa_off {
		pins_cmd0_dat {
			pinmux = <PINMUX_GPIO174__FUNC_GPIO174>;
		};
		pins_cmd1_dat {
			pinmux = <PINMUX_GPIO170__FUNC_GPIO170>;
		};
		pins_cmd2_dat {
			pinmux = <PINMUX_GPIO171__FUNC_GPIO171>;
		};
		pins_cmd3_dat {
			pinmux = <PINMUX_GPIO172__FUNC_GPIO172>;
		};
	};

	aud_pins_smartpa_on: aud_pins_smartpa_on {
		pins_cmd0_dat {
			pinmux = <PINMUX_GPIO174__FUNC_I2S0_DI>;
		};
		pins_cmd1_dat {
			pinmux = <PINMUX_GPIO170__FUNC_I2S3_BCK>;
		};
		pins_cmd2_dat {
			pinmux = <PINMUX_GPIO171__FUNC_I2S3_LRCK>;
		};
		pins_cmd3_dat {
			pinmux = <PINMUX_GPIO172__FUNC_I2S3_DO>;
		};
	};

	vow_dat_miso_off: vow_dat_miso_off {
		pins_cmd1_dat {
			pinmux = <PINMUX_GPIO142__FUNC_GPIO142>;
		};
	};

	vow_dat_miso_on: vow_dat_miso_on {
		pins_cmd1_dat {
			pinmux = <PINMUX_GPIO142__FUNC_VOW_DAT_MISO>;
		};
	};

	vow_clk_miso_off: vow_clk_miso_off {
		pins_cmd3_dat {
			pinmux = <PINMUX_GPIO143__FUNC_GPIO143>;
		};
	};

	vow_clk_miso_on: vow_clk_miso_on {
		pins_cmd3_dat {
			pinmux = <PINMUX_GPIO143__FUNC_VOW_CLK_MISO>;
		};
	};
};*/
/* AUDIO end */
//#endif /* VENDOR_EDIT */

/* CONSYS GPIO standardization */
&pio {
	consys_pins_default: consys_default {
	};
	gpslna_pins_init: gpslna@0 {
		pins_cmd_dat {
			pinmux = <PINMUX_GPIO169__FUNC_GPIO169>;
			//#ifndef VENDOR_EDIT
			//Wenjie.Liu@PSW.CN.GPS.Hardware.Power.1202743, 2017/12/29,
			//modify for: [GPS_LNA gpio's output direction is out]
			/*
			slew-rate = <0>;
			*/
			//#else /* VENDOR_EDIT */
			slew-rate = <1>;
			//#endif /* VENDOR_EDIT */
			bias-disable;
			output-low;
		};
	};
	gpslna_pins_oh: gpslna@1 {
		pins_cmd_dat {
			pinmux = <PINMUX_GPIO169__FUNC_GPIO169>;
			slew-rate = <1>;
			output-high;
		};
	};
	gpslna_pins_ol: gpslna@2 {
		pins_cmd_dat {
			pinmux = <PINMUX_GPIO169__FUNC_GPIO169>;
			slew-rate = <1>;
			output-low;
		};
	};
};
&consys {
	pinctrl-names = "default", "gps_lna_state_init", "gps_lna_state_oh", "gps_lna_state_ol";
	pinctrl-0 = <&consys_pins_default>;
	pinctrl-1 = <&gpslna_pins_init>;
	pinctrl-2 = <&gpslna_pins_oh>;
	pinctrl-3 = <&gpslna_pins_ol>;
	status = "okay";
};
/* CONSYS end */

/* IRTX GPIO Start */
&irtx_pwm {
	pinctrl-names = "irtx_gpio_led_default", "irtx_gpio_led_set";
	pinctrl-0 = <&irtx_gpio_led_default>;
	pinctrl-1 = <&irtx_gpio_led_set>;
	status = "okay";
};
&pio {
	/* IRTX GPIO Settings -Start */
	/* default: GPIO0, output, high */
	irtx_gpio_led_default:irtx_gpio_led_def@gpio90 {
		pins_cmd_dat {
			pinmux = <PINMUX_GPIO90__FUNC_GPIO90>;
			slew-rate = <1>;
			bias-disable;
			output-low;
			input-schmitt-enable = <0>;
		};
	};

	irtx_gpio_led_set:irtx_gpio_led_set@gpio90 {
		pins_cmd_dat {
			pinmux = <PINMUX_GPIO90__FUNC_PWM_A>;
			slew-rate = <1>;
			output-high;
		};
	};
}; /* IRTX GPIO Settings -End */

&mt6370_pmu {
	mt6370,intr_gpio_num = <10>; /* direct defined GPIO num */
	mt6370,intr_gpio = <&pio 10 0x0>;
};

&mt6370_typec {
	mt6370pd,intr_gpio_num = <41>; /* direct defined GPIO num */
	mt6370pd,intr_gpio = <&pio 41 0x0>;
};

/* USB TYPEC GPIO start */
&pio {
	usb_default: usb_default {
	};

	gpio_redriver_c1_init: c1_init {
		pins_cmd_dat {
			pinmux = <PINMUX_GPIO18__FUNC_GPIO18>;
			slew-rate = <1>;
			output-low;
		};
	};

	gpio_redriver_c1_low: c1_low {
		pins_cmd_dat {
			pinmux = <PINMUX_GPIO18__FUNC_GPIO18>;
			slew-rate = <1>;
			output-low;
		};
	};

	gpio_redriver_c1_hiz: c1_highz {
		pins_cmd_dat {
			pinmux = <PINMUX_GPIO18__FUNC_GPIO18>;
			slew-rate= <0>;
			bias-disable;
		};
	};

	gpio_redriver_c1_high: c1_high {
		pins_cmd_dat {
			pinmux = <PINMUX_GPIO18__FUNC_GPIO18>;
			slew-rate = <1>;
			output-high;
		};
	};

	gpio_redriver_c2_init: c2_init {
		pins_cmd_dat {
			pinmux = <PINMUX_GPIO17__FUNC_GPIO17>;
			slew-rate = <1>;
			output-low;
		};
	};

	gpio_redriver_c2_low: c2_low {
		pins_cmd_dat {
			pinmux = <PINMUX_GPIO17__FUNC_GPIO17>;
			slew-rate = <1>;
			output-low;
		};
	};

	gpio_redriver_c2_hiz: c2_highz {
		pins_cmd_dat {
			pinmux = <PINMUX_GPIO17__FUNC_GPIO17>;
			slew-rate= <0>;
			bias-disable;
		};
	};

	gpio_redriver_c2_high: c2_high {
		pins_cmd_dat {
			pinmux = <PINMUX_GPIO17__FUNC_GPIO17>;
			slew-rate = <1>;
			output-high;
		};
	};

	gpio_u3_switch_sel1: u3_sw_sel1 {
		pins_cmd_dat {
			pinmux = <PINMUX_GPIO177__FUNC_GPIO177>;
			slew-rate = <1>;
			output-low;
		};
	};

	gpio_u3_switch_sel2: u3_sw_sel2 {
		pins_cmd_dat {
			pinmux = <PINMUX_GPIO177__FUNC_GPIO177>;
			slew-rate = <1>;
			output-high;
		};
	};

	gpio_u3_switch_enable: u3_sw_en {
	};

	gpio_u3_switch_disable: u3_sw_dis {
	};
};

&usb_c_pinctrl {
	pinctrl-names = "usb_default",
		"redrv_c1_init",
		"redrv_c1_low",
		"redrv_c1_hiz",
		"redrv_c1_high",
		"redrv_c2_init",
		"redrv_c2_low",
		"redrv_c2_hiz",
		"redrv_c2_high",
		"switch_sel1",
		"switch_sel2",
		"switch_enable",
		"switch_disable";

	pinctrl-0 = <&usb_default>;
	pinctrl-1 = <&gpio_redriver_c1_init>;
	pinctrl-2 = <&gpio_redriver_c1_low>;
	pinctrl-3 = <&gpio_redriver_c1_hiz>;
	pinctrl-4 = <&gpio_redriver_c1_high>;
	pinctrl-5 = <&gpio_redriver_c2_init>;
	pinctrl-6 = <&gpio_redriver_c2_low>;
	pinctrl-7 = <&gpio_redriver_c2_hiz>;
	pinctrl-8 = <&gpio_redriver_c2_high>;
	pinctrl-9 = <&gpio_u3_switch_sel1>;
	pinctrl-10 = <&gpio_u3_switch_sel2>;
	pinctrl-11 = <&gpio_u3_switch_enable>;
	pinctrl-12 = <&gpio_u3_switch_disable>;
	status = "okay";

	usb_switch-data {
		en_pin_num = <0>;
		en_pin_val = <0>; /*DISABLE=0 ENABLE=1*/
		sel_pin_num = <177>;
		sel_pin_val = <1>; /*CC1=1, CC2=2*/
		c1_pin_num = <18>;
		c1_pin_val = <2>; /*Low=0, HighZ=1, High=2*/
		c2_pin_num = <17>;
		c2_pin_val = <1>;
	};
};
/* USB TYPEC GPIO end */

//#ifdef VENDOR_EDIT
/* Bin.Li@EXP.BSP.bootloader.bootflow, 2017/05/16, Add volume up and down */
&keypad {
	keypad,volume-up	= <&pio 20 0x00>;
	keypad,volume-down	= <&pio 94 0x00>;
	pinctrl-names = "volume_up_as_int", "volume_down_as_int";
	pinctrl-0 = <&volume_up_gpio_eint>;
	pinctrl-1 = <&volume_down_gpio_eint>;
	status = "okay";
};

&pio {
	volume_up_gpio_eint:volume_up@0{
		pins_cmd_dat {
			pinmux = <PINMUX_GPIO20__FUNC_GPIO20>;
			slew-rate = <0>;  /*direction 0:in, 1:out*/
			bias-pull-up = <00>;
			input-enable;
		};
	};
	volume_down_gpio_eint:volume_down@0{
		pins_cmd_dat {
			pinmux = <PINMUX_GPIO94__FUNC_GPIO94>;
			slew-rate = <0>;  /*direction 0:in, 1:out*/
			bias-pull-up = <00>;
			input-enable;
		};
	};
};
//#endif /*VENDOR_EDIT*/

//#ifdef VENDOR_EDIT
/* chaochao.xie.BSP.bootloader.bootflow, 2019/10/19, Add for T-card ldo */
&msdc1{
	pinctrl-names = "msdc1_on","msdc1_off";
	pinctrl-0 = <&msdc1_on>;
	pinctrl-1 = <&msdc1_off>;
	status = "okay";
};
&pio {
	msdc1_on:sd0@0{
		pins_cmd_dat {
			pinmux = <PINMUX_GPIO90__FUNC_GPIO90>;
			slew-rate = <1>;
			output-high;
		};
    };
	msdc1_off: sd0@1 {
		pins_cmd_dat {
			pinmux = <PINMUX_GPIO90__FUNC_GPIO90>;
			slew-rate = <1>;
			output-low;
		};
	};
};
//#endif /*VENDOR_EDIT*/

&charger {
	algorithm_name = "DualSwitchCharging";
	chg1_ta_ac_charger_current = <2000000>;
	chg2_ta_ac_charger_current = <2000000>;
};
&pio {
	charger_pins_default: eint0default {
	};
	charger_pins_eint_output0: charger_gpio_as_output_low {
		pins_cmd_dat {
			pinmux = <PINMUX_GPIO97__FUNC_GPIO97>;
			slew-rate = <1>;
			output-low;
		};
	};
	charger_pins_eint_output1: charger_gpio_as_output_high {
		pins_cmd_dat {
			pinmux = <PINMUX_GPIO97__FUNC_GPIO97>;
			slew-rate = <1>;
			output-high;
		};
	};

	ship_sleep_gpio: ship_sleep {
		pins_cmd_dat {
			pinmux = <PINMUX_GPIO155__FUNC_GPIO155>;
			slew-rate = <1>;
			output-low;
		};
	};
	ship_active_gpio: ship_active {
		pins_cmd_dat {
			pinmux = <PINMUX_GPIO155__FUNC_GPIO155>;
			slew-rate = <1>;
			output-high;
		};
	};
	shortc_active_gpio: shortc_active {
		pins_cmd_dat {
			pinmux = <PINMUX_GPIO77__FUNC_GPIO77>;
			input-enable;
			slew-rate = <0>;
			bias-pull-up;
		};
	};
};

//#ifdef VENDOR_EDIT
//Fuchun.Liao@BSP.CHG.Basic 2017/11/18 modify for use bq24190 charger
&i2c6 {
	bq27541-battery@55 {
		status = "okay";
		compatible = "oppo,bq27541-battery";
		reg = <0x55 0>;
		qcom,modify-soc-smooth;
	};
/*
	pic16f_fastcg@25{
		status = "okay";
		compatible = "oppo,pic16f-fastcg";
		reg = <0x25 0>;

		pinctrl-names = "switch1_act_switch2_act", "switch1_sleep_switch2_sleep",
						"switch1_act_switch3_act", "switch1_sleep_switch3_sleep",
						"switch1_act_switch2_sleep", "switch1_sleep_switch2_act",
						"clock_active","clock_sleep",
						"data_active","data_sleep",
						"reset_active","reset_sleep";
		pinctrl-0 = <&charging_switch1_active>;
		pinctrl-1 = <&charging_switch1_sleep >;
		pinctrl-2 = <&charging_switch1_active>;
		pinctrl-3 = <&charging_switch1_sleep >;
		pinctrl-4 = <&charging_switch1_active>;
		pinctrl-5 = <&charging_switch1_sleep>;
		pinctrl-6 = <&charging_clock_active >;
		pinctrl-7 = <&charging_clock_sleep >;
		pinctrl-8 = <&charging_data_active >;
		pinctrl-9 = <&charging_data_sleep >;
		pinctrl-10 = <&charging_reset_active >;
		pinctrl-11 = <&charging_reset_sleep >;
	};
		
	n76e_fastcg@52{
		status = "okay";
		compatible = "oppo,n76e-fastcg";
		reg = <0x52 0>;
		qcom,oppo_batt_4400mv;
		////qcom,vooc_fw_update_newmethod;

		pinctrl-names = "switch1_act_switch2_act", "switch1_sleep_switch2_sleep",
						"switch1_act_switch3_act", "switch1_sleep_switch3_sleep",
						"switch1_act_switch2_sleep", "switch1_sleep_switch2_act",
						"clock_active","clock_sleep",
						"data_active","data_sleep",
						"reset_active","reset_sleep";
		pinctrl-0 = <&charging_switch1_active>;
		pinctrl-1 = <&charging_switch1_sleep>;
		pinctrl-2 = <&charging_switch1_active>;
		pinctrl-3 = <&charging_switch1_sleep>;
		pinctrl-4 = <&charging_switch1_active>;
		pinctrl-5 = <&charging_switch1_sleep>;
		pinctrl-6 = <&charging_clock_active>;
		pinctrl-7 = <&charging_clock_sleep>;
		pinctrl-8 = <&charging_data_active>;
		pinctrl-9 = <&charging_data_sleep>;
		pinctrl-10 = <&charging_reset_active>;
		pinctrl-11 = <&charging_reset_sleep>;

		qcom,charging_switch1-gpio 		= <&pio 166 0x00>;
		//qcom,charging_switch2-gpio 		= <&tlmm 113 0x00>;
		//qcom,charging_switch3-gpio 		= <&tlmm 38 0x00>;

		qcom,charging_reset-gpio 			= <&pio 160 0x00>;
		qcom,charging_clock-gpio 			= <&pio 25 0x00>;
		qcom,charging_data-gpio 			= <&pio 26 0x00>;
	};
*/
	stm8s_fastcg@26{
		status = "okay";
		compatible = "oppo,stm8s-fastcg";
		reg = <0x26 0>;
		qcom,vooc-low-temp = <120>;
		qcom,oppo_batt_4400mv;
		qcom,vooc_fw_update_newmethod;
		qcom,vooc-fw-type = <7>;

		pinctrl-names = "switch1_act_switch2_act", "switch1_sleep_switch2_sleep",
						"switch1_act_switch3_act", "switch1_sleep_switch3_sleep",
						"switch1_act_switch2_sleep", "switch1_sleep_switch2_act",
						"clock_active","clock_sleep",
						"data_active","data_sleep",
						"reset_active","reset_sleep";
		pinctrl-0 = <&charging_switch1_active>;
		pinctrl-1 = <&charging_switch1_sleep>;
		pinctrl-2 = <&charging_switch1_active>;
		pinctrl-3 = <&charging_switch1_sleep>;
		pinctrl-4 = <&charging_switch1_active>;
		pinctrl-5 = <&charging_switch1_sleep>;
		pinctrl-6 = <&charging_clock_active>;
		pinctrl-7 = <&charging_clock_sleep>;
		pinctrl-8 = <&charging_data_active>;
		pinctrl-9 = <&charging_data_sleep>;
		pinctrl-10 = <&charging_reset_active>;
		pinctrl-11 = <&charging_reset_sleep>;

		qcom,charging_switch1-gpio 		= <&pio 166 0x00>;
		//qcom,charging_switch2-gpio 		= <&tlmm 113 0x00>;
		//qcom,charging_switch3-gpio 		= <&tlmm 38 0x00>;

		qcom,charging_reset-gpio 			= <&pio 160 0x00>;
		qcom,charging_clock-gpio 			= <&pio 25 0x00>;
		qcom,charging_data-gpio 			= <&pio 26 0x00>;
	};
};
//#endif /* VENDOR_EDIT */

&pio {
	charging_switch1_active: charging_switch1_active {
		pins_cmd_dat {
			pinmux = <PINMUX_GPIO166__FUNC_GPIO166>;
			slew-rate = <1>;
			output-high;
		};
	};
	charging_switch1_sleep: charging_switch1_sleep {
		pins_cmd_dat {
			pinmux = <PINMUX_GPIO166__FUNC_GPIO166>;
			slew-rate = <1>;
			output-low;
		};
	};
	charging_clock_active: charging_clock_active {
		pins_cmd_dat {
			pinmux = <PINMUX_GPIO25__FUNC_GPIO25>;
			slew-rate = <0>;
			bias-pull-up = <00>;
		};
	};
	charging_clock_sleep: charging_clock_sleep {
		pins_cmd_dat {
			pinmux = <PINMUX_GPIO25__FUNC_GPIO25>;
			slew-rate = <0>;
			bias-pull-down = <00>;
		};
	};
	charging_data_active: charging_data_active {
		pins_cmd_dat {
			pinmux = <PINMUX_GPIO26__FUNC_GPIO26>;
			slew-rate = <0>;
			bias-pull-up = <00>;
		};
	};
	charging_data_sleep: charging_data_sleep {
		pins_cmd_dat {
			pinmux = <PINMUX_GPIO26__FUNC_GPIO26>;
			slew-rate = <0>;
			bias-pull-down = <00>;
		};
	};
	charging_reset_active: charging_reset_active {
		pins_cmd_dat {
			pinmux = <PINMUX_GPIO160__FUNC_GPIO160>;
			slew-rate = <1>;
			output-high;
		};
	};
	charging_reset_sleep: charging_reset_sleep {
		pins_cmd_dat {
			pinmux = <PINMUX_GPIO160__FUNC_GPIO160>;
			slew-rate = <1>;
			output-low;
		};
	};
};


//#ifdef VENDOR_EDIT
/*Yangzhenxuan@BSP.TP.Function, 2019/8/24, add for himax noflash*/

/*&spi3 {
        #address-cells = <1>;
        #size-cells = <0>;
        spidev2: spi@2 {
                compatible = "mediatek,spi-mt65xx-test";
                reg = <0>;
                spi-max-frequency = <1000000>;
        };
};
*/

&spi3 {
    /* Novatek device tree node */
    status = "ok";
    #address-cells = <1>;
    #size-cells = <0>;
    touchscreen@0 {
        status = "okay";                                                                               
        compatible = "oppo,tp_noflash";
        reg = <0>;
        chip-name = "OPPO_TP_NOFLASH";

        spi-max-frequency = <9600000>; //4800000,9600000,15000000,19200000
        reset-gpio = <&pio 42 0x00>;
        interrupt-parent = <&pio>;
        interrupts = <1 IRQ_TYPE_EDGE_RISING 1 0>;
        irq-gpio = <&pio 1 0x2001>;
        lcd-reset-gpio = <&pio 45 0x00>;

        synaptics,irq-on-state = <0>;
        synaptics,reset-on-state = <0>;
        synaptics,reset-active-ms = <20>;
        synaptics,reset-delay-ms = <200>;
        synaptics,power-delay-ms = <200>;
        synaptics,spi-mode = <3>;
        synaptics,byte-delay-us = <0>;
        synaptics,block-delay-us = <0>;
        synaptics,ubl-max-freq = <1000000>;
        synaptics,ubl-byte-delay-us = <20>;
        synaptics,grip-darkzone-area = <0xF4 0x45>;
        synaptics,irq_trigger_hdl_support;
        touchpanel,max-num-support = <10>;
        touchpanel,tx-rx-num = <16 36>;
        touchpanel,panel-coords = <1080 2340>;
        touchpanel,display-coords = <1080 2340>;

        incell_screen;
        fw_edge_limit_support;
        black_gesture_support;
        charger_pump_support;
        headset_pump_support;
        //spurious_fingerprint_support;
        //lcd_trigger_fp_check;
        black_gesture_test_support;
        game_switch_support;
        noflash_support;
        lcd_trigger_load_tp_fw_support;
        smart_gesture_support;
        fw_update_app_support;
        pressure_report_support;
        freq_hop_simulate_support;

        /*
        *Virtual Key Config:
        *1:touchpanel,button-type: <virtualkey_type  supportted_button-map>
        *virtualkey_type:
        *Type 1: using board_properties
        *Type 2: using same IC (button zone&& touch zone are seprate)
        *Type 3: using diffrent IC (button zone&& touch zone are seprate)
        *Type 4: No need of virtual key process
        *supportted_button-map:select|menu|home|back
        *
        *2:touchpanel,button-map
        *type (X1,Y1)(X2,Y2)(X3,Y3)(Width_X,Hight_Y)--Only when button-type is 0
        */

        touchpanel,button-type = <4>;
    };
};
//#endif

//Fuchun.Liao@BSP.CHG.Basic 2017/11/24 modify for oppo dws
#include <oppo6771_17197/cust.dtsi>
//#endif /* VENDOR_EDIT */
#include "cust_mt6771_camera.dtsi"
/*End of this file, DO NOT ADD ANYTHING HERE*/


